AUTOSAR XML (schema 4-2-2)
package /ComponentTypes
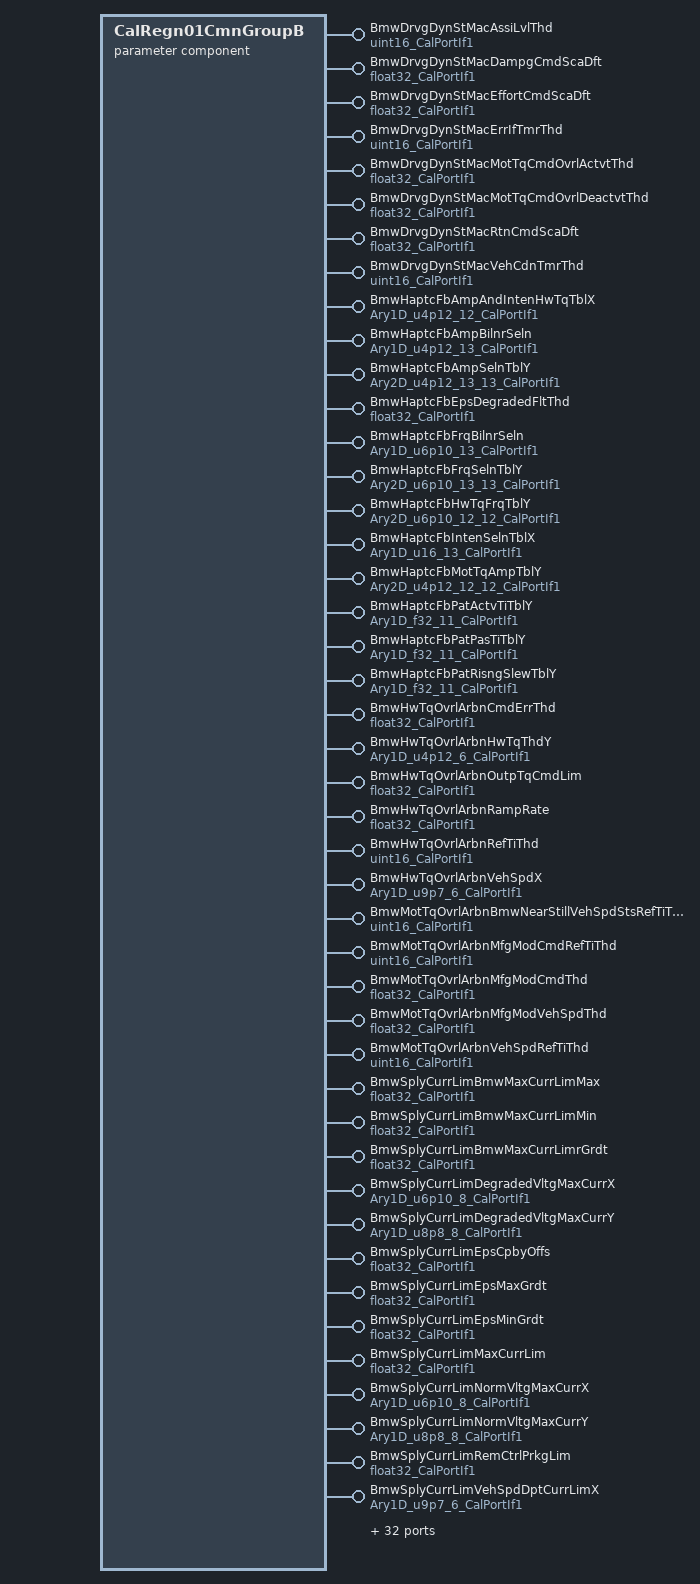
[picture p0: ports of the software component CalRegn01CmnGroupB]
  parameter sw component type CalRegn01CmnGroupB
    76 x provide port:
      BmwDrvgDynStMacAssiLvlThd: parameter-provide-com-spec{init-value=20, parameter=Val}, provided-interface=uint16_CalPortIf1
      BmwDrvgDynStMacDampgCmdScaDft: parameter-provide-com-spec{init-value=1, parameter=Val}, provided-interface=float32_CalPortIf1
      BmwDrvgDynStMacEffortCmdScaDft: parameter-provide-com-spec{init-value=1, parameter=Val}, provided-interface=float32_CalPortIf1
      BmwDrvgDynStMacErrIfTmrThd: parameter-provide-com-spec{init-value=20, parameter=Val}, provided-interface=uint16_CalPortIf1
      BmwDrvgDynStMacMotTqCmdOvrlActvtThd: parameter-provide-com-spec{init-value=0, parameter=Val}, provided-interface=float32_CalPortIf1
      BmwDrvgDynStMacMotTqCmdOvrlDeactvtThd: parameter-provide-com-spec{init-value=0, parameter=Val}, provided-interface=float32_CalPortIf1
      BmwDrvgDynStMacRtnCmdScaDft: parameter-provide-com-spec{init-value=1, parameter=Val}, provided-interface=float32_CalPortIf1
      BmwDrvgDynStMacVehCdnTmrThd: parameter-provide-com-spec{init-value=20, parameter=Val}, provided-interface=uint16_CalPortIf1
      BmwHaptcFbAmpAndIntenHwTqTblX: parameter-provide-com-spec{init-value=[0, 4096, 8192, 12288, 16384, 20480, 24576, 28672, 32768, 36864, 38912, 40960], parameter=Ary1D}, provided-interface=Ary1D_u4p12_12_CalPortIf1
      BmwHaptcFbAmpBilnrSeln: parameter-provide-com-spec{init-value=[0, 4096, 8192, 12288, 16384, 20480, 24576, 28672, 32768, 36864, 40960, 40960, 40960], parameter=Ary1D}, provided-interface=Ary1D_u4p12_13_CalPortIf1
      BmwHaptcFbAmpSelnTblY: parameter-provide-com-spec{init-value=13 x [0, 40960, 40960, 40960, 40960, 40960, 40960, 40960, 40960, 40960, 40960, 40960, 40960], parameter=Ary2D}, provided-interface=Ary2D_u4p12_13_13_CalPortIf1
      BmwHaptcFbEpsDegradedFltThd: parameter-provide-com-spec{init-value=0.9, parameter=Val}, provided-interface=float32_CalPortIf1
      BmwHaptcFbFrqBilnrSeln: parameter-provide-com-spec{init-value=[30720, 10240, 30720, 10240, 40960, 40960, 40960, 20480, 20480, 46080, 20480, 46080, 51200], parameter=Ary1D}, provided-interface=Ary1D_u6p10_13_CalPortIf1
      BmwHaptcFbFrqSelnTblY: parameter-provide-com-spec{init-value=[[30720, 10240, 30720, 10240, 40960, 40960, 40960, 20480, 20480, 46080, 20480, 46080, 51200], [31744, 12288, 31744, 13312, 41984, 30720, 30720, 40960, 20480, 15360, 15360, 46080, 51200], [32768, 14336, 32768, 16384, 43008, 51200, 51200, 20480, 20480, 20480, 46080, 46080, 51200], [33792, 16384, 33792, 18432, 44032, 20480, 20480, 15360, 15360, 15360, 18432, 46080, 51200], [34816, 17408, 34816, 20480, 45056, 10240, 15360, 46080, 46080, 18432, 15360, 46080, 51200], [17408, 18432, 35840, 22528, 46080, 15360, 51200, 18432, 18432, 15360, 51200, 15360, 51200], [19456, 19456, 36864, 24576, 47104, 51200, 46080, 51200, 51200, 20480, 51200, 15360, 51200], [20480, 20480, 37888, 26624, 48128, 18432, 18432, 18432, 51200, 18432, 51200, 18432, 51200], [30720, 21504, 38912, 28672, 49152, 28672, 51200, 46080, 20480, 18432, 51200, 18432, 51200], [30720, 22528, 39936, 30720, 51200, 46080, 20480, 30720, 18432, 18432, 51200, 18432, 51200], [30720, 22528, 39936, 30720, 51200, 46080, 20480, 30720, 18432, 18432, 51200, 18432, 51200], [30720, 22528, 39936, 30720, 51200, 46080, 20480, 30720, 18432, 18432, 51200, 18432, 51200], [30720, 22528, 39936, 30720, 51200, 46080, 20480, 30720, 18432, 18432, 51200, 18432, 51200]], parameter=Ary2D}, provided-interface=Ary2D_u6p10_13_13_CalPortIf1
      BmwHaptcFbHwTqFrqTblY: parameter-provide-com-spec{init-value=[[30720, 10240, 30720, 10240, 40960, 40960, 40960, 20480, 20480, 46080, 20480, 46080], [31744, 12288, 31744, 13312, 41984, 30720, 30720, 40960, 20480, 15360, 15360, 46080], [32768, 14336, 32768, 16384, 43008, 51200, 51200, 20480, 20480, 20480, 46080, 46080], [33792, 16384, 33792, 18432, 44032, 20480, 20480, 15360, 15360, 15360, 18432, 46080], [34816, 17408, 34816, 20480, 45056, 10240, 15360, 46080, 46080, 18432, 15360, 46080], [17408, 18432, 35840, 22528, 46080, 15360, 51200, 18432, 18432, 15360, 51200, 15360], [19456, 19456, 36864, 24576, 47104, 51200, 46080, 51200, 51200, 20480, 51200, 15360], [20480, 20480, 37888, 26624, 48128, 18432, 18432, 18432, 51200, 18432, 51200, 18432], [30720, 21504, 38912, 28672, 49152, 28672, 51200, 46080, 20480, 18432, 51200, 18432], [30720, 22528, 39936, 30720, 51200, 46080, 20480, 30720, 18432, 18432, 51200, 18432], [30720, 22528, 39936, 30720, 51200, 46080, 20480, 30720, 18432, 18432, 51200, 18432], [30720, 22528, 39936, 30720, 51200, 46080, 20480, 30720, 18432, 18432, 51200, 18432]], parameter=Ary2D}, provided-interface=Ary2D_u6p10_12_12_CalPortIf1
      BmwHaptcFbIntenSelnTblX: parameter-provide-com-spec{init-value=[0, 1, 2, 3, 4, 5, 6, 7, 8, 9, 10, 11, 12], parameter=Ary1D}, provided-interface=Ary1D_u16_13_CalPortIf1
      BmwHaptcFbMotTqAmpTblY: parameter-provide-com-spec{init-value=12 x [0, 1229, 1229, 1229, 1229, 1229, 1229, 1229, 1229, 1229, 1229, 1229], parameter=Ary2D}, provided-interface=Ary2D_u4p12_12_12_CalPortIf1
      BmwHaptcFbPatActvTiTblY: parameter-provide-com-spec{init-value=[0, 0.1, 0.2, 0.3, 0.4, 0.5, 0.6, 0.7, 0.8, 0.9, 3], parameter=Ary1D}, provided-interface=Ary1D_f32_11_CalPortIf1
      BmwHaptcFbPatPasTiTblY: parameter-provide-com-spec{init-value=[0, 0, 0.1, 0.2, 0.3, 0.4, 0.5, 0.6, 0.7, 0.8, 1], parameter=Ary1D}, provided-interface=Ary1D_f32_11_CalPortIf1
      BmwHaptcFbPatRisngSlewTblY: parameter-provide-com-spec{init-value=[0.1, 24.4, 13.2, 10, 15, 5, 10, 15, 20, 26, 30], parameter=Ary1D}, provided-interface=Ary1D_f32_11_CalPortIf1
      BmwHwTqOvrlArbnCmdErrThd: parameter-provide-com-spec{init-value=0.1, parameter=Val}, provided-interface=float32_CalPortIf1
      BmwHwTqOvrlArbnHwTqThdY: parameter-provide-com-spec{init-value=[12288, 12288, 8192, 4096, 0, 0], parameter=Ary1D}, provided-interface=Ary1D_u4p12_6_CalPortIf1
      BmwHwTqOvrlArbnOutpTqCmdLim: parameter-provide-com-spec{init-value=3, parameter=Val}, provided-interface=float32_CalPortIf1
      BmwHwTqOvrlArbnRampRate: parameter-provide-com-spec{init-value=10, parameter=Val}, provided-interface=float32_CalPortIf1
      BmwHwTqOvrlArbnRefTiThd: parameter-provide-com-spec{init-value=500, parameter=Val}, provided-interface=uint16_CalPortIf1
      BmwHwTqOvrlArbnVehSpdX: parameter-provide-com-spec{init-value=[0, 1280, 2560, 6400, 12800, 25600], parameter=Ary1D}, provided-interface=Ary1D_u9p7_6_CalPortIf1
      BmwMotTqOvrlArbnBmwNearStillVehSpdStsRefTiThd: parameter-provide-com-spec{init-value=10, parameter=Val}, provided-interface=uint16_CalPortIf1
      BmwMotTqOvrlArbnMfgModCmdRefTiThd: parameter-provide-com-spec{init-value=10, parameter=Val}, provided-interface=uint16_CalPortIf1
      BmwMotTqOvrlArbnMfgModCmdThd: parameter-provide-com-spec{init-value=0, parameter=Val}, provided-interface=float32_CalPortIf1
      BmwMotTqOvrlArbnMfgModVehSpdThd: parameter-provide-com-spec{init-value=10, parameter=Val}, provided-interface=float32_CalPortIf1
      BmwMotTqOvrlArbnVehSpdRefTiThd: parameter-provide-com-spec{init-value=10, parameter=Val}, provided-interface=uint16_CalPortIf1
      BmwSplyCurrLimBmwMaxCurrLimMax: parameter-provide-com-spec{init-value=120, parameter=Val}, provided-interface=float32_CalPortIf1
      BmwSplyCurrLimBmwMaxCurrLimMin: parameter-provide-com-spec{init-value=43, parameter=Val}, provided-interface=float32_CalPortIf1
      BmwSplyCurrLimBmwMaxCurrLimrGrdt: parameter-provide-com-spec{init-value=20, parameter=Val}, provided-interface=float32_CalPortIf1
      BmwSplyCurrLimDegradedVltgMaxCurrX: parameter-provide-com-spec{init-value=[7168, 10240, 11264, 14336, 17408, 20480, 27648, 32768], parameter=Ary1D}, provided-interface=Ary1D_u6p10_8_CalPortIf1
      BmwSplyCurrLimDegradedVltgMaxCurrY: parameter-provide-com-spec{init-value=[0, 10880, 10880, 10880, 10880, 10880, 10880, 10880], parameter=Ary1D}, provided-interface=Ary1D_u8p8_8_CalPortIf1
      BmwSplyCurrLimEpsCpbyOffs: parameter-provide-com-spec{init-value=0, parameter=Val}, provided-interface=float32_CalPortIf1
      BmwSplyCurrLimEpsMaxGrdt: parameter-provide-com-spec{init-value=50000, parameter=Val}, provided-interface=float32_CalPortIf1
      BmwSplyCurrLimEpsMinGrdt: parameter-provide-com-spec{init-value=200, parameter=Val}, provided-interface=float32_CalPortIf1
      BmwSplyCurrLimMaxCurrLim: parameter-provide-com-spec{init-value=120, parameter=Val}, provided-interface=float32_CalPortIf1
      BmwSplyCurrLimNormVltgMaxCurrX: parameter-provide-com-spec{init-value=[6400, 6912, 7168, 9216, 10240, 11264, 14336, 27648], parameter=Ary1D}, provided-interface=Ary1D_u6p10_8_CalPortIf1
      BmwSplyCurrLimNormVltgMaxCurrY: parameter-provide-com-spec{init-value=[0, 10880, 10880, 15360, 25600, 30720, 30720, 15360], parameter=Ary1D}, provided-interface=Ary1D_u8p8_8_CalPortIf1
      BmwSplyCurrLimRemCtrlPrkgLim: parameter-provide-com-spec{init-value=120, parameter=Val}, provided-interface=float32_CalPortIf1
      BmwSplyCurrLimVehSpdDptCurrLimX: parameter-provide-com-spec{init-value=[0, 640, 1280, 2560, 6400, 12800], parameter=Ary1D}, provided-interface=Ary1D_u9p7_6_CalPortIf1
      BmwSplyCurrLimVehSpdDptCurrLimY: parameter-provide-com-spec{init-value=[30720, 30720, 26880, 21760, 15360, 15360], parameter=Ary1D}, provided-interface=Ary1D_u8p8_6_CalPortIf1
      BmwSplyCurrLimVltgDptCurrGrdtDecX: parameter-provide-com-spec{init-value=[10752, 11776, 17920, 18944, 20480, 24576, 27648, 32768], parameter=Ary1D}, provided-interface=Ary1D_u6p10_8_CalPortIf1
      BmwSplyCurrLimVltgDptCurrGrdtDecY: parameter-provide-com-spec{init-value=[50000, 50000, 50000, 800, 800, 800, 800, 800], parameter=Ary1D}, provided-interface=Ary1D_u16p0_8_CalPortIf1
      BmwSplyCurrLimVltgDptCurrGrdtIncX: parameter-provide-com-spec{init-value=[10752, 11776, 17920, 18944, 20480, 24576, 27648, 32768], parameter=Ary1D}, provided-interface=Ary1D_u6p10_8_CalPortIf1
      BmwSplyCurrLimVltgDptCurrGrdtIncY: parameter-provide-com-spec{init-value=[800, 50000, 50000, 50000, 50000, 50000, 50000, 50000], parameter=Ary1D}, provided-interface=Ary1D_u16p0_8_CalPortIf1
      BmwSplyCurrLimVltgDptCurrLimFltThd: parameter-provide-com-spec{init-value=55, parameter=Val}, provided-interface=float32_CalPortIf1
      BmwSplyCurrLimVrntMaxCurr: parameter-provide-com-spec{init-value=120, parameter=Val}, provided-interface=float32_CalPortIf1
      BmwTqOvrlCdngAndDrvgDynFacActvDampgSlewRate: parameter-provide-com-spec{init-value=500, parameter=Val}, provided-interface=float32_CalPortIf1
      BmwTqOvrlCdngAndDrvgDynFacActvEffortSlewRate: parameter-provide-com-spec{init-value=500, parameter=Val}, provided-interface=float32_CalPortIf1
      BmwTqOvrlCdngAndDrvgDynFacActvRtnSlewRate: parameter-provide-com-spec{init-value=500, parameter=Val}, provided-interface=float32_CalPortIf1
      BmwTqOvrlCdngAndDrvgDynFacDampgScaLoLimX: parameter-provide-com-spec{init-value=[0, 1164, 2327, 3491, 4655, 5818, 6982, 8145, 9309, 10473, 11636, 12800], parameter=Ary1D}, provided-interface=Ary1D_u11p5_12_CalPortIf1
      BmwTqOvrlCdngAndDrvgDynFacDampgScaLoLimY: parameter-provide-com-spec{init-value=12 x 12 x 0, parameter=Ary2D}, provided-interface=Ary2D_u1p15_12_12_CalPortIf1
      BmwTqOvrlCdngAndDrvgDynFacEffortScaHiLimX: parameter-provide-com-spec{init-value=[0, 3724, 7447, 11171, 14895, 18618, 22342, 26065, 29789, 33513, 37236, 40960], parameter=Ary1D}, provided-interface=Ary1D_u4p12_12_CalPortIf1
      BmwTqOvrlCdngAndDrvgDynFacEffortScaHiLimY: parameter-provide-com-spec{init-value=12 x 12 x 32768, parameter=Ary2D}, provided-interface=Ary2D_u2p14_12_12_CalPortIf1
      BmwTqOvrlCdngAndDrvgDynFacInactvDampgSlewRate: parameter-provide-com-spec{init-value=500, parameter=Val}, provided-interface=float32_CalPortIf1
      BmwTqOvrlCdngAndDrvgDynFacInactvEffortSlewRate: parameter-provide-com-spec{init-value=500, parameter=Val}, provided-interface=float32_CalPortIf1
      BmwTqOvrlCdngAndDrvgDynFacInactvRtnSlewRate: parameter-provide-com-spec{init-value=500, parameter=Val}, provided-interface=float32_CalPortIf1
      BmwTqOvrlCdngAndDrvgDynFacOutpTqOvrlSlew: parameter-provide-com-spec{init-value=2, parameter=Val}, provided-interface=float32_CalPortIf1
      BmwTqOvrlCdngAndDrvgDynFacReqdRtnCmdScaLoLim: parameter-provide-com-spec{init-value=0, parameter=Val}, provided-interface=float32_CalPortIf1
      BmwTqOvrlCdngAndDrvgDynFacTarSteerTqDrvrActrLpFilFrq: parameter-provide-com-spec{init-value=0.3, parameter=Val}, provided-interface=float32_CalPortIf1
      BmwTqOvrlCdngAndDrvgDynFacTarSteerTqDrvrActrMaxY: parameter-provide-com-spec{init-value=[14336, 12288, 10240, 8192, 6144, 4096, 3072, 2048, 1024, 410], parameter=Ary1D}, provided-interface=Ary1D_u4p12_10_CalPortIf1
      BmwTqOvrlCdngAndDrvgDynFacTarSteerTqDrvrActrSpdX: parameter-provide-com-spec{init-value=[0, 256, 1280, 3200, 6400, 9600, 12800, 19200, 25600, 31872], parameter=Ary1D}, provided-interface=Ary1D_u9p7_10_CalPortIf1
      BmwTrfcJamAssiDampgBasDampgX: parameter-provide-com-spec{init-value=[0, 960, 1920, 2880, 3840, 4800, 5760, 6720, 7680, 9600], parameter=Ary1D}, provided-interface=Ary1D_u11p5_10_CalPortIf1
      BmwTrfcJamAssiDampgBasDampgY: parameter-provide-com-spec{init-value=10 x 0, parameter=Ary1D}, provided-interface=Ary1D_u4p12_10_CalPortIf1
      BmwTrfcJamAssiDampgLimdDampgX: parameter-provide-com-spec{init-value=[0, 873, 1745, 2618, 3491, 4364, 5236, 6109, 6982, 7855, 8727, 9600], parameter=Ary1D}, provided-interface=Ary1D_u11p5_12_CalPortIf1
      BmwTrfcJamAssiDampgLimdDampgY: parameter-provide-com-spec{init-value=12 x 12 x 36045, parameter=Ary2D}, provided-interface=Ary2D_u4p12_12_12_CalPortIf1
      BmwTrfcJamAssiDampgLimExcddFltRefTiThd: parameter-provide-com-spec{init-value=10, parameter=Val}, provided-interface=uint16_CalPortIf1
      BmwTrfcJamAssiDampgRatThd: parameter-provide-com-spec{init-value=0.9, parameter=Val}, provided-interface=float32_CalPortIf1
      BmwTrfcJamAssiDampgSlewRateDwnActv: parameter-provide-com-spec{init-value=1000, parameter=Val}, provided-interface=float32_CalPortIf1
      BmwTrfcJamAssiDampgSlewRateDwnInactv: parameter-provide-com-spec{init-value=1000, parameter=Val}, provided-interface=float32_CalPortIf1
      BmwTrfcJamAssiDampgSlewRateDwnInvld: parameter-provide-com-spec{init-value=1000, parameter=Val}, provided-interface=float32_CalPortIf1
      BmwTrfcJamAssiDampgSlewRateUp: parameter-provide-com-spec{init-value=1000, parameter=Val}, provided-interface=float32_CalPortIf1
